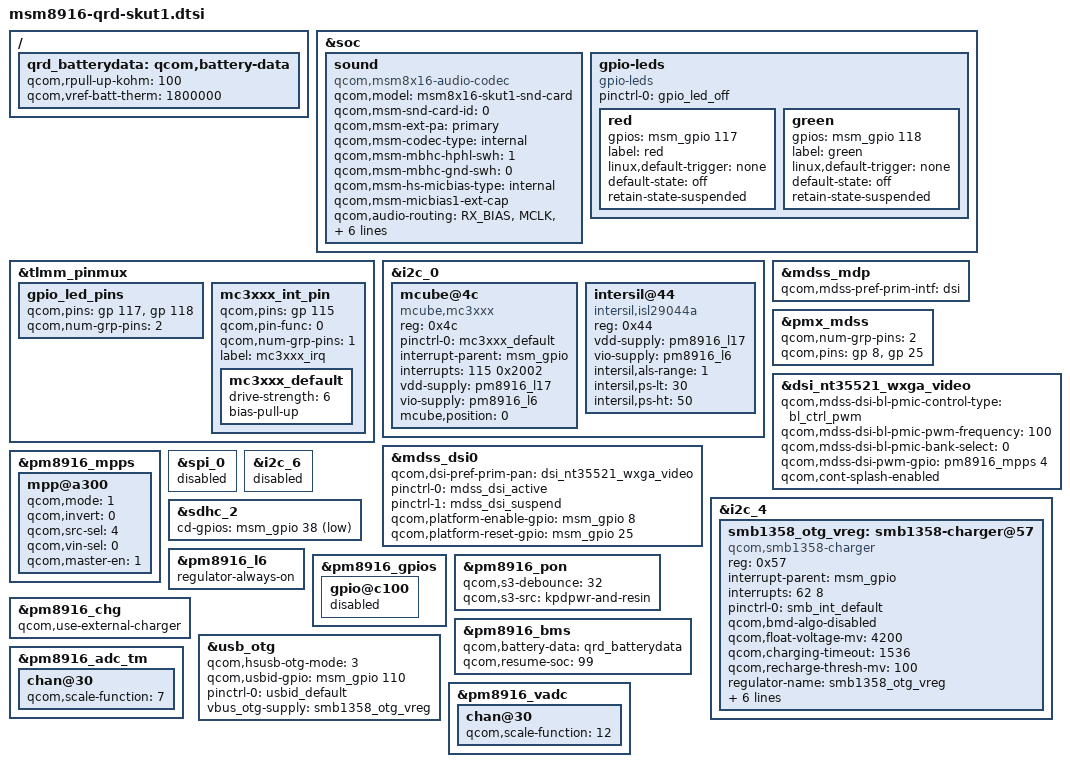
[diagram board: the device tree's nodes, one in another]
/*
 * Copyright (c) 2014, The Linux Foundation. All rights reserved.
 *
 * This program is free software; you can redistribute it and/or modify
 * it under the terms of the GNU General Public License version 2 and
 * only version 2 as published by the Free Software Foundation.
 *
 * This program is distributed in the hope that it will be useful,
 * but WITHOUT ANY WARRANTY; without even the implied warranty of
 * MERCHANTABILITY or FITNESS FOR A PARTICULAR PURPOSE.  See the
 * GNU General Public License for more details.
 */

#include "msm8916-qrd.dtsi"
#include "dsi-panel-nt35521-wxga-video.dtsi"
#include "msm8916-camera-sensor-qrd-skui.dtsi"

&soc {
	sound {
		compatible = "qcom,msm8x16-audio-codec";
		qcom,model = "msm8x16-skut1-snd-card";
		qcom,msm-snd-card-id = <0>;
		qcom,msm-ext-pa = "primary";
		qcom,msm-codec-type = "internal";
		qcom,msm-mbhc-hphl-swh = <1>;
		qcom,msm-mbhc-gnd-swh = <0>;
		qcom,msm-hs-micbias-type = "internal";
		qcom,msm-micbias1-ext-cap;
		qcom,audio-routing =
			"RX_BIAS", "MCLK",
			"SPK_RX_BIAS", "MCLK",
			"INT_LDO_H", "MCLK",
			"MIC BIAS External", "Handset Mic",
			"MIC BIAS Internal2", "Headset Mic",
			"AMIC1", "MIC BIAS External",
			"AMIC2", "MIC BIAS Internal2";
		pinctrl-names = "cdc_lines_act",
				"cdc_lines_sus";
		pinctrl-0 = <&cdc_pdm_lines_act>;
		pinctrl-1 = <&cdc_pdm_lines_sus>;
	};

	gpio-leds {
		compatible = "gpio-leds";
		status = "okay";
		pinctrl-names = "default";
		pinctrl-0 = <&gpio_led_off>;

		red {
			gpios = <&msm_gpio 117 0>;
			label = "red";
			linux,default-trigger = "none";
			default-state = "off";
			retain-state-suspended;
		};

		green {
			gpios = <&msm_gpio 118 0>;
			label = "green";
			linux,default-trigger = "none";
			default-state = "off";
			retain-state-suspended;
		};
	};
};

&tlmm_pinmux {
	gpio_led_pins {
		qcom,pins = <&gp 117>, <&gp 118>;
		qcom,num-grp-pins = <2>;
	};

	mc3xxx_int_pin {
		qcom,pins = <&gp 115>;
		qcom,pin-func = <0>;
		qcom,num-grp-pins = <1>;
		label = "mc3xxx_irq";
		mc3xxx_default: mc3xxx_default {
			drive-strength = <6>;
			bias-pull-up;
		};
	};
};

&i2c_0 { /* BLSP1 QUP2 */
	mcube@4c { /* Accelerometer sensor */
		compatible = "mcube,mc3xxx";
		reg = <0x4c>;
		pinctrl-names = "default";
		pinctrl-0 = <&mc3xxx_default>;
		interrupt-parent = <&msm_gpio>;
		interrupts = <115 0x2002>;
		vdd-supply = <&pm8916_l17>;
		vio-supply = <&pm8916_l6>;
		mcube,position = <0>;
	};
};

&i2c_0 { /* BLSP1 QUP2 */
	intersil@44 { /* Ambient light and proximity sensor */
		compatible = "intersil,isl29044a";
		reg = <0x44>;
		vdd-supply = <&pm8916_l17>;
		vio-supply = <&pm8916_l6>;
		intersil,als-range = <1>;
		intersil,ps-lt = <30>;
		intersil,ps-ht = <50>;
	};
};

&mdss_mdp {
	qcom,mdss-pref-prim-intf = "dsi";
};

&pmx_mdss {
	qcom,num-grp-pins = <2>;
	qcom,pins = <&gp 8>, <&gp 25>;
};

&mdss_dsi0 {
	qcom,dsi-pref-prim-pan = <&dsi_nt35521_wxga_video>;
	pinctrl-names = "mdss_default", "mdss_sleep";
	pinctrl-0 = <&mdss_dsi_active>;
	pinctrl-1 = <&mdss_dsi_suspend>;

	qcom,platform-enable-gpio = <&msm_gpio 8 0>;
	qcom,platform-reset-gpio = <&msm_gpio 25 0>;
};

&dsi_nt35521_wxga_video {
	qcom,mdss-dsi-bl-pmic-control-type = "bl_ctrl_pwm";
	qcom,mdss-dsi-bl-pmic-pwm-frequency = <100>;
	qcom,mdss-dsi-bl-pmic-bank-select = <0>;
	qcom,mdss-dsi-pwm-gpio = <&pm8916_mpps 4 0>;
	qcom,cont-splash-enabled;
};

&pm8916_mpps {
	mpp@a300 { /* MPP 4 */
		/* Backlight PWM */
		qcom,mode = <1>;		/* Digital output */
		qcom,invert = <0>;		/* Disable invert */
		qcom,src-sel = <4>;		/* DTEST1 */
		qcom,vin-sel = <0>;		/* VPH_PWR */
		qcom,master-en = <1>;		/* Enable MPP */
	};
};

&i2c_4 { /* BLSP1 QUP4 */
	smb1358_otg_vreg: smb1358-charger@57 {
		compatible = "qcom,smb1358-charger";
		reg = <0x57>;
		interrupt-parent = <&msm_gpio>;
		interrupts = <62 8>;
		pinctrl-names = "default";
		pinctrl-0 = <&smb_int_default>;
		qcom,bmd-algo-disabled;
		qcom,float-voltage-mv = <4200>;
		qcom,charging-timeout = <1536>;
		qcom,recharge-thresh-mv = <100>;
		regulator-name = "smb1358_otg_vreg";
		qcom,soft-vfloat-comp-disabled;
		qcom,thermal-mitigation = <1500 700 600 0>;
		qcom,bms-psy-name = "bms";
		qcom,bms-controlled-charging;
		qcom,iterm-disabled;
		qcom,inhibit-disabled;
	};
};

&spi_0 {
	status = "disabled";
};

&i2c_6 {
	status = "disabled";
};

&sdhc_2 {
	cd-gpios = <&msm_gpio 38 0x1>;
};

&pm8916_l6 {
	regulator-always-on;
};

&pm8916_gpios {
	gpio@c100 { /* GPIO 2 */
		/* NFC_CLK_REQ */
		status = "disabled";
	};
};

&pm8916_pon {
	qcom,s3-debounce = <32>;
	qcom,s3-src = "kpdpwr-and-resin";
};

/ {
	qrd_batterydata: qcom,battery-data {
		qcom,rpull-up-kohm = <100>;
		qcom,vref-batt-therm = <1800000>;

		#include "batterydata-qrd-4v2-2200mah.dtsi"
	};
};

&pm8916_chg {
	status = "ok";
	qcom,use-external-charger;
};

&pm8916_bms {
	status = "ok";
	qcom,battery-data = <&qrd_batterydata>;
	qcom,resume-soc = <99>;
	/delete-node/ qcom,batt-pres-status@1208;
};

&usb_otg {
	qcom,hsusb-otg-mode = <3>;
	qcom,usbid-gpio = <&msm_gpio 110 0>;
	pinctrl-names = "default";
	pinctrl-0 = <&usbid_default>;
	vbus_otg-supply = <&smb1358_otg_vreg>;
};

&pm8916_vadc {
	chan@30 {
		qcom,scale-function = <12>;
	};
};

&pm8916_adc_tm {
	chan@30 {
		qcom,scale-function = <7>;
	};
};
